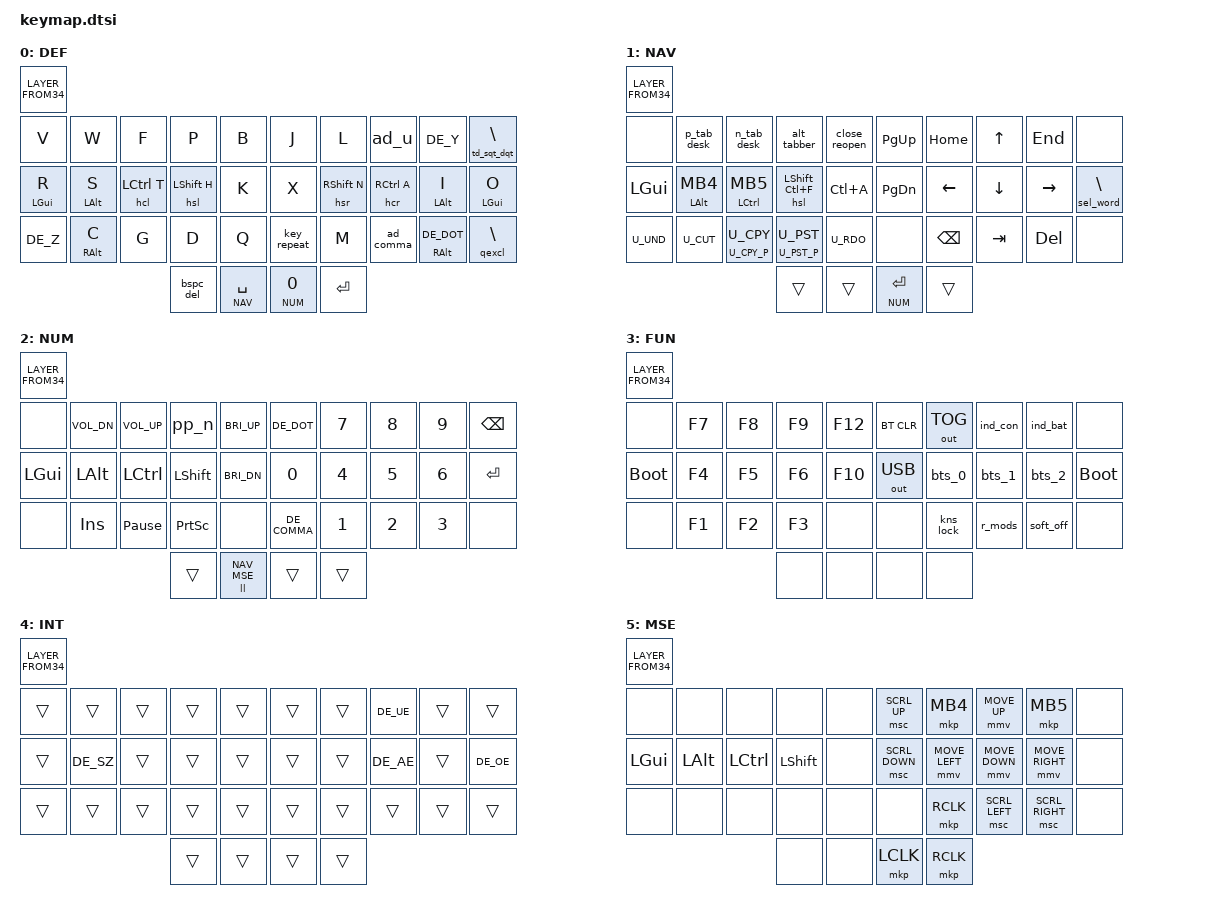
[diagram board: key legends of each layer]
/*
 * Copyright (c) 2020 The ZMK Contributors
 *
 * SPDX-License-Identifier: MIT
 */

#include <dt-bindings/zmk/bt.h>
#include <dt-bindings/zmk/keys.h>
#include <dt-bindings/zmk/mouse.h>
#include <dt-bindings/zmk/outputs.h>

#ifndef KEYMAP_DRAWER
#include "include/keys_de.h"
#endif

#define DEF 0
#define NAV 1
#define NUM 2
#define FUN 3
#define INT 4
#define MSE 5

#define CT(KEY) &mt LC(KEY) KEY

#define MEH     LC(LS(LALT))
#define HYPER   LC(LS(LA(LGUI)))

#define U_RDO   LC(DE_Y)
#define U_PST   LC(V)
#define U_PST_P LS(LC(V))
#define U_CPY   LC(C)
#define U_CPY_P LS(LC(C))
#define U_CUT   LC(X)
#define U_UND   LC(DE_Z)

#include "include/keypos.h"
#include "behaviors.dtsi"
#include "combos.dtsi"
#include "macros.dtsi"
#include "mouse.dtsi"

/ {
    conditional_layers {
        compatible = "zmk,conditional-layers";

        tri_layer  {
            if-layers = <NAV NUM>;
            then-layer = <FUN>;
        };
    };

    keymap {
        compatible = "zmk,keymap";

        default_layer {
            display-name = "DEF";
            bindings = <LAYER_FROM34( \
// ╭─────────────┬─────────────┬─────────────┬──────────────┬──────────────╮   ╭─────────────┬─────────────┬─────────────┬─────────────────┬─────────────╮
    &kp V,        &kp W,        &kp F,        &kp P,         &kp B,             &kp J,        &kp L,        &ad_u,        &kp DE_Y,         &td_sqt_dqt, \
// ├─────────────┼─────────────┼─────────────┼──────────────┼──────────────┤   ├─────────────┼─────────────┼─────────────┼─────────────────┼─────────────┤
    &hml LGUI R,  &hml LALT S,  &hcl LCTRL T, &hsl LSHIFT H, &kp K,             &kp X,        &hsr RSHFT N, &hcr RCTRL A, &hmr LALT I,      &hmr LGUI O, \
// ├─────────────┼─────────────┼─────────────┼──────────────┼──────────────┤   ├─────────────┼─────────────┼─────────────┼─────────────────┼─────────────┤
    &kp DE_Z,     &hml RALT C,  &kp G,        &kp D,         &kp Q,             &key_repeat,  &kp M,        &ad_comma,    &hmr RALT DE_DOT, &qexcl,      \
// ╰─────────────┴─────────────┴─────────────┼──────────────┼──────────────┤   ├─────────────┼─────────────┼─────────────┴─────────────────┴─────────────╯
                                              &bspc_del,     &lt NAV SPACE,     &lt_e NUM 0,  &kp RET      \
//                                           ╰──────────────┴──────────────╯   ╰─────────────┴─────────────╯
            )>;
        };

        navigation_layer {
            display-name = "NAV";
            bindings = <LAYER_FROM34( \
// ╭─────────────┬────────────────┬──────────────────┬──────────────────┬──────────────╮   ╭─────────────┬─────────────┬─────────────┬─────────────┬─────────────╮
    &none,        &p_tab_desk,     &n_tab_desk,       &alt_tabber,       &close_reopen,     &kp PG_UP,    &kp HOME,     &kp UP,       &kp END,      &none,       \
// ├─────────────┼────────────────┼──────────────────┼──────────────────┼──────────────┤   ├─────────────┼─────────────┼─────────────┼─────────────┼─────────────┤
    &kp LGUI,     &hml_m LALT MB4, &hml_m LCTRL MB5,  &hsl LSHFT LC(F),  &kp LC(A),         &kp PG_DN,    &kp LEFT,     &kp DOWN,     &kp RIGHT,    &sel_word,   \
// ├─────────────┼────────────────┼──────────────────┼──────────────────┼──────────────┤   ├─────────────┼─────────────┼─────────────┼─────────────┼─────────────┤
    &kp U_UND,    &kp U_CUT,       &mt U_CPY_P U_CPY, &mt U_PST_P U_PST, &kp U_RDO,         &none,        &kp BSPC,     &kp TAB,      &kp DEL,      &none,       \
// ╰─────────────┴────────────────┴──────────────────┼──────────────────┼──────────────┤   ├─────────────┼─────────────┼─────────────┴─────────────┴─────────────╯
                                                      &trans,            &trans,            &lt NUM RET,  &trans       \
//                                                   ╰──────────────────┴──────────────╯   ╰─────────────┴─────────────╯
            )>;
        };

        number_layer {
            display-name = "NUM";
            bindings = <LAYER_FROM34( \
// ╭─────────────┬─────────────┬────────────────┬─────────────┬─────────────╮   ╭─────────────┬─────────────┬─────────────┬─────────────┬─────────────╮
    &none,        &kp C_VOL_DN, &kp C_VOL_UP,    &pp_n,        &kp C_BRI_UP,     &kp DE_DOT,   &kp N7,       &kp N8,       &kp N9,       &kp BSPC,    \
// ├─────────────┼─────────────┼────────────────┼─────────────┼─────────────┤   ├─────────────┼─────────────┼─────────────┼─────────────┼─────────────┤
    &kp LGUI,     &kp LALT,     &kp LCTRL,       &kp LSHFT,    &kp C_BRI_DN,     &kp N0,       &kp N4,       &kp N5,       &kp N6,       &kp RET,     \
// ├─────────────┼─────────────┼────────────────┼─────────────┼─────────────┤   ├─────────────┼─────────────┼─────────────┼─────────────┼─────────────┤
    &none,        &kp INS,      &kp PAUSE_BREAK, &kp PSCRN,    &none,            &kp DE_COMMA, &kp N1,       &kp N2,       &kp N3,       &none,       \
// ╰─────────────┴─────────────┴────────────────┼─────────────┼─────────────┤   ├─────────────┼─────────────┼─────────────┴─────────────┴─────────────╯
                                                 &trans,       &ll NAV MSE,      &trans,       &trans       \
//                                              ╰─────────────┴─────────────╯   ╰─────────────┴─────────────╯
            )>;
        };

        function_layer {
            display-name = "FUN";
            bindings = <LAYER_FROM34( \
// ╭─────────────┬─────────────┬─────────────┬─────────────┬─────────────╮   ╭─────────────┬─────────────┬─────────────┬────────────────┬─────────────╮
    &none,        &kp F7,       &kp F8,       &kp F9,       &kp F12,          &bt BT_CLR,   &out OUT_TOG, &ind_con,     &ind_bat,        &none,       \
// ├─────────────┼─────────────┼─────────────┼─────────────┼─────────────┤   ├─────────────┼─────────────┼─────────────┼────────────────┼─────────────┤
    &bootloader,  &kp F4,       &kp F5,       &kp F6,       &kp F10,          &out OUT_USB, &bts_0,       &bts_1,       &bts_2,          &bootloader, \
// ├─────────────┼─────────────┼─────────────┼─────────────┼─────────────┤   ├─────────────┼─────────────┼─────────────┼────────────────┼─────────────┤
    &none,        &kp F1,       &kp F2,       &kp F3,       &none,            &none,        &kns_lock,    &r_mods,      &soft_off,       &none,       \
// ╰─────────────┴─────────────┴─────────────┼─────────────┼─────────────┤   ├─────────────┼─────────────┼─────────────┴────────────────┴─────────────╯
                                              &none,        &none,            &none,        &none
//                                           ╰─────────────┴─────────────╯   ╰─────────────┴─────────────╯
            )>;
        }; 

        international_layer {
            display-name = "INT";
            bindings = <LAYER_FROM34( \
// ╭─────────────┬─────────────┬─────────────┬─────────────┬─────────────╮   ╭─────────────┬─────────────┬─────────────┬─────────────┬─────────────╮
    &trans,       &trans,       &trans,       &trans,       &trans,           &trans,       &trans,       &kp DE_UE,    &trans,       &trans,      \
// ├─────────────┼─────────────┼─────────────┼─────────────┼─────────────┤   ├─────────────┼─────────────┼─────────────┼─────────────┼─────────────┤
    &trans,       &kp DE_SZ,    &trans,       &trans,       &trans,           &trans,       &trans,       &kp DE_AE,    &trans,       &kp DE_OE,   \
// ├─────────────┼─────────────┼─────────────┼─────────────┼─────────────┤   ├─────────────┼─────────────┼─────────────┼─────────────┼─────────────┤
    &trans,       &trans,       &trans,       &trans,       &trans,           &trans,       &trans,       &trans,       &trans,       &trans,      \
// ╰─────────────┴─────────────┴─────────────┼─────────────┼─────────────┤   ├─────────────┼─────────────┼─────────────┴─────────────┴─────────────╯
                                              &trans,       &trans,           &trans,       &trans       \
//                                           ╰─────────────┴─────────────╯   ╰─────────────┴─────────────╯
            )>;
        };

        mouse_layer {
            display-name = "MSE";
            bindings = <LAYER_FROM34( \
// ╭─────────────┬─────────────┬─────────────┬─────────────┬─────────────╮   ╭───────────────┬───────────────┬───────────────┬────────────────┬─────────────╮
    &none,        &none,        &none,        &none,        &none,            &msc SCRL_UP,   &mkp MB4,       &mmv MOVE_UP,   &mkp MB5,        &none,       \
// ├─────────────┼─────────────┼─────────────┼─────────────┼─────────────┤   ├───────────────┼───────────────┼───────────────┼────────────────┼─────────────┤
    &kp LGUI,     &kp LALT,     &kp LCTRL,    &kp LSHFT,    &none,            &msc SCRL_DOWN, &mmv MOVE_LEFT, &mmv MOVE_DOWN, &mmv MOVE_RIGHT, &none,       \
// ├─────────────┼─────────────┼─────────────┼─────────────┼─────────────┤   ├───────────────┼───────────────┼───────────────┼────────────────┼─────────────┤
    &none,        &none,        &none,        &none,        &none,            &none,          &mkp RCLK,      &msc SCRL_LEFT, &msc SCRL_RIGHT, &none,       \
// ╰─────────────┴─────────────┴─────────────┼─────────────┼─────────────┤   ├───────────────┼───────────────┼───────────────┴────────────────┴─────────────╯
                                              &none,        &none,            &mkp LCLK,      &mkp RCLK      \
//                                           ╰─────────────┴─────────────╯   ╰───────────────┴───────────────╯
            )>;
        };

        extra1 {
            status = "reserved";
        };

        extra2 {
            status = "reserved";
        };
    };
};
